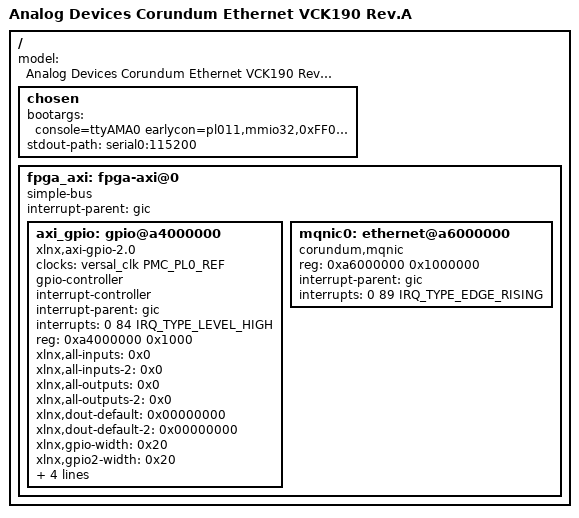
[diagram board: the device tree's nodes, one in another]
// SPDX-License-Identifier: GPL-2.0
/*
 * Corundum NIC on the VCK190 QSFP28 cage (MRMAC, 1x100GE CAUI-4)
 *
 * hdl_project: <corundum/100g/vck190>
 * board_revision: <>
 *
 * Copyright (C) 2026 Analog Devices Inc.
 */

#include "versal-vck190-revA.dts"
#include <dt-bindings/interrupt-controller/irq.h>

/ {
	model = "Analog Devices Corundum Ethernet VCK190 Rev.A";

	chosen {
		bootargs = "console=ttyAMA0 earlycon=pl011,mmio32,0xFF000000,115200n8 clk_ignore_unused root=/dev/mmcblk0p2 rw rootfstype=ext4 rootwait";
		stdout-path = "serial0:115200";
	};

	fpga_axi: fpga-axi@0 {
		interrupt-parent = <&gic>;
		compatible = "simple-bus";
		#address-cells = <0x1>;
		#size-cells = <0x1>;
		ranges = <0 0 0 0xffffffff>;

		/* channel 1 bits 4/5 (GPIO 36/37) are QSFP MODPRSL/INTL inputs */
		axi_gpio: gpio@a4000000 {
			#gpio-cells = <2>;
			#interrupt-cells = <2>;
			clock-names = "s_axi_aclk";
			clocks = <&versal_clk PMC_PL0_REF>;
			compatible = "xlnx,axi-gpio-2.0", "xlnx,xps-gpio-1.00.a";
			gpio-controller;
			interrupt-controller;
			interrupt-names = "ip2intc_irpt";
			interrupt-parent = <&gic>;
			interrupts = <0 84 IRQ_TYPE_LEVEL_HIGH>;
			reg = <0xa4000000 0x1000>;
			xlnx,all-inputs = <0x0>;
			xlnx,all-inputs-2 = <0x0>;
			xlnx,all-outputs = <0x0>;
			xlnx,all-outputs-2 = <0x0>;
			xlnx,dout-default = <0x00000000>;
			xlnx,dout-default-2 = <0x00000000>;
			xlnx,gpio-width = <0x20>;
			xlnx,gpio2-width = <0x20>;
			xlnx,interrupt-present = <0x1>;
			xlnx,is-dual = <0x1>;
			xlnx,tri-default = <0xFFFFFFFF>;
			xlnx,tri-default-2 = <0xFFFFFFFF>;
		};

		mqnic0: ethernet@a6000000 {
			compatible = "corundum,mqnic";
			reg = <0xa6000000 0x1000000>;
			interrupt-parent = <&gic>;
			interrupts = <0 89 IRQ_TYPE_EDGE_RISING>;
		};
	};
};
